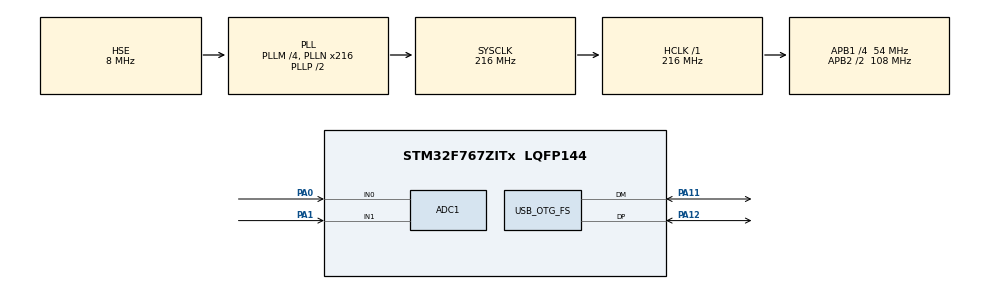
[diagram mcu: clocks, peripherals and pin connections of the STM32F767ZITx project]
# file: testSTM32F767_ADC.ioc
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ADC1.Channel-2\#ChannelRegularConversion=ADC_CHANNEL_1
ADC1.ClockPrescaler=ADC_CLOCK_SYNC_PCLK_DIV4
ADC1.ContinuousConvMode=ENABLE
ADC1.DMAContinuousRequests=ENABLE
ADC1.EOCSelection=ADC_EOC_SINGLE_CONV
ADC1.NbrOfConversion=2
ADC1.NbrOfConversionFlag=1
ADC1.Rank-2\#ChannelRegularConversion=2
ADC1.SamplingTime-0\#ChannelRegularConversion=ADC_SAMPLETIME_144CYCLES
ADC1.SamplingTime-2\#ChannelRegularConversion=ADC_SAMPLETIME_144CYCLES
ADC1.ScanConvMode=ADC_SCAN_ENABLE
ADC1.master=1
CORTEX_M7.ART_ACCLERATOR_ENABLE=1
CORTEX_M7.CPU_DCache=Enabled
CORTEX_M7.CPU_ICache=Enabled
CORTEX_M7.PREFETCH_ENABLE=1
Dma.ADC1.0.Direction=DMA_PERIPH_TO_MEMORY
Dma.ADC1.0.FIFOMode=DMA_FIFOMODE_DISABLE
Dma.ADC1.0.Instance=DMA2_Stream0
Dma.ADC1.0.MemDataAlignment=DMA_MDATAALIGN_HALFWORD
Dma.ADC1.0.MemInc=DMA_MINC_ENABLE
Dma.ADC1.0.Mode=DMA_CIRCULAR
Dma.ADC1.0.PeriphDataAlignment=DMA_PDATAALIGN_HALFWORD
Dma.ADC1.0.PeriphInc=DMA_PINC_DISABLE
Dma.ADC1.0.Priority=DMA_PRIORITY_MEDIUM
Dma.Request0=ADC1
Mcu.Family=STM32F7
Mcu.Name=STM32F767ZITx
Mcu.Package=LQFP144
NVIC.DMA2_Stream0_IRQn=true\:0\:0\:false\:false\:true\:false\:true
NVIC.OTG_FS_IRQn=true\:0\:0\:false\:false\:true\:false\:true
NVIC.PriorityGroup=NVIC_PRIORITYGROUP_4
NVIC.TIM2_IRQn=true\:0\:0\:false\:false\:true\:true\:true
PA0/WKUP.Signal=ADCx_IN0
PA1.Signal=ADCx_IN1
PA11.Mode=Device_Only
PA11.Signal=USB_OTG_FS_DM
PA12.Mode=Device_Only
PA12.Signal=USB_OTG_FS_DP
PH0/OSC_IN.Mode=HSE-External-Oscillator
PH0/OSC_IN.Signal=RCC_OSC_IN
PH1/OSC_OUT.Mode=HSE-External-Oscillator
PH1/OSC_OUT.Signal=RCC_OSC_OUT
ProjectManager.HeapSize=0x200
ProjectManager.StackSize=0x400
ProjectManager.TargetToolchain=SW4STM32
RCC.AHBFreq_Value=216000000
RCC.APB1CLKDivider=RCC_HCLK_DIV4
RCC.APB1Freq_Value=54000000
RCC.APB1TimFreq_Value=108000000
RCC.APB2CLKDivider=RCC_HCLK_DIV2
RCC.APB2Freq_Value=108000000
RCC.APB2TimFreq_Value=216000000
RCC.CortexFreq_Value=216000000
RCC.HCLKFreq_Value=216000000
RCC.HSE_VALUE=8000000
RCC.HSI_VALUE=16000000
RCC.LSE_VALUE=32768
RCC.PLLM=4
RCC.PLLN=216
RCC.PLLQ=9
RCC.SYSCLKFreq_VALUE=216000000
RCC.SYSCLKSource=RCC_SYSCLKSOURCE_PLLCLK
RCC.USBFreq_Value=48000000
RCC.VCOOutputFreq_Value=432000000
SH.ADCx_IN0.0=ADC1_IN0,IN0
SH.ADCx_IN1.0=ADC1_IN1,IN1
TIM2.Period=100
TIM2.Prescaler=5000
TIM2.TIM_MasterOutputTrigger=TIM_TRGO_UPDATE
USB_DEVICE.CLASS_NAME_FS=CDC
USB_DEVICE.VirtualMode-CDC_FS=Cdc
USB_DEVICE.VirtualModeFS=Cdc_FS
USB_OTG_FS.VirtualMode=Device_Only
VP_TIM2_VS_ClockSourceINT.Mode=Internal
VP_USB_DEVICE_VS_USB_DEVICE_CDC_FS.Mode=CDC_FS
board=custom

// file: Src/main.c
/* USER CODE BEGIN Header */
/**
  ******************************************************************************
  * @file           : main.c
  * @brief          : Main program body
  ******************************************************************************
  * @attention
  *
  * <h2><center>&copy; Copyright (c) 2020 STMicroelectronics.
  * All rights reserved.</center></h2>
  *
  * This software component is licensed by ST under BSD 3-Clause license,
  * the "License"; You may not use this file except in compliance with the
  * License. You may obtain a copy of the License at:
  *                        opensource.org/licenses/BSD-3-Clause
  *
  ******************************************************************************
  */
/* USER CODE END Header */

#include "main.h"
#include "usb_device.h"

ADC_HandleTypeDef hadc1;
DMA_HandleTypeDef hdma_adc1;

TIM_HandleTypeDef htim2;

void SystemClock_Config(void);
static void MX_GPIO_Init(void);
static void MX_DMA_Init(void);
static void MX_ADC1_Init(void);
static void MX_TIM2_Init(void);

/* USER CODE BEGIN 0 */
uint16_t adcdata[2]={0};

/* USER CODE END 0 */

int main(void)
{

  /* Enable I-Cache---------------------------------------------------------*/
  SCB_EnableICache();

  /* Enable D-Cache---------------------------------------------------------*/
  SCB_EnableDCache();

  /* MCU Configuration--------------------------------------------------------*/

  /* Reset of all peripherals, Initializes the Flash interface and the Systick. */
  HAL_Init();

  /* Configure the system clock */
  SystemClock_Config();

  /* Initialize all configured peripherals */
  MX_GPIO_Init();
  MX_DMA_Init();
  MX_ADC1_Init();
  MX_TIM2_Init();
  MX_USB_DEVICE_Init();
  /* USER CODE BEGIN 2 */

  HAL_ADC_Start_DMA(&hadc1, adcdata, sizeof(adcdata));
  uint8_t sendbuf[10]="Loop...";
  /* USER CODE END 2 */

  /* Infinite loop */
  while (1)
  {

    /* USER CODE BEGIN 3 */
	  HAL_Delay(10);
	  CDC_Transmit_FS(sendbuf, sizeof(sendbuf));
  }
  /* USER CODE END 3 */
}

void SystemClock_Config(void)
{
  RCC_OscInitTypeDef RCC_OscInitStruct = {0};
  RCC_ClkInitTypeDef RCC_ClkInitStruct = {0};
  RCC_PeriphCLKInitTypeDef PeriphClkInitStruct = {0};

  /** Configure the main internal regulator output voltage
  */
  __HAL_RCC_PWR_CLK_ENABLE();
  __HAL_PWR_VOLTAGESCALING_CONFIG(PWR_REGULATOR_VOLTAGE_SCALE1);
  /** Initializes the CPU, AHB and APB busses clocks
  */
  RCC_OscInitStruct.OscillatorType = RCC_OSCILLATORTYPE_HSE;
  RCC_OscInitStruct.HSEState = RCC_HSE_ON;
  RCC_OscInitStruct.PLL.PLLState = RCC_PLL_ON;
  RCC_OscInitStruct.PLL.PLLSource = RCC_PLLSOURCE_HSE;
  RCC_OscInitStruct.PLL.PLLM = 4;
  RCC_OscInitStruct.PLL.PLLN = 216;
  RCC_OscInitStruct.PLL.PLLP = RCC_PLLP_DIV2;
  RCC_OscInitStruct.PLL.PLLQ = 9;
  if (HAL_RCC_OscConfig(&RCC_OscInitStruct) != HAL_OK)
  {
    Error_Handler();
  }
  /** Activate the Over-Drive mode
  */
  if (HAL_PWREx_EnableOverDrive() != HAL_OK)
  {
    Error_Handler();
  }
  /** Initializes the CPU, AHB and APB busses clocks
  */
  RCC_ClkInitStruct.ClockType = RCC_CLOCKTYPE_HCLK|RCC_CLOCKTYPE_SYSCLK
                              |RCC_CLOCKTYPE_PCLK1|RCC_CLOCKTYPE_PCLK2;
  RCC_ClkInitStruct.SYSCLKSource = RCC_SYSCLKSOURCE_PLLCLK;
  RCC_ClkInitStruct.AHBCLKDivider = RCC_SYSCLK_DIV1;
  RCC_ClkInitStruct.APB1CLKDivider = RCC_HCLK_DIV4;
  RCC_ClkInitStruct.APB2CLKDivider = RCC_HCLK_DIV2;

  if (HAL_RCC_ClockConfig(&RCC_ClkInitStruct, FLASH_LATENCY_7) != HAL_OK)
  {
    Error_Handler();
  }
  PeriphClkInitStruct.PeriphClockSelection = RCC_PERIPHCLK_CLK48;
  PeriphClkInitStruct.Clk48ClockSelection = RCC_CLK48SOURCE_PLL;
  if (HAL_RCCEx_PeriphCLKConfig(&PeriphClkInitStruct) != HAL_OK)
  {
    Error_Handler();
  }
}

static void MX_ADC1_Init(void)
{

  ADC_ChannelConfTypeDef sConfig = {0};

  /** Configure the global features of the ADC (Clock, Resolution, Data Alignment and number of conversion)
  */
  hadc1.Instance = ADC1;
  hadc1.Init.ClockPrescaler = ADC_CLOCK_SYNC_PCLK_DIV4;
  hadc1.Init.Resolution = ADC_RESOLUTION_12B;
  hadc1.Init.ScanConvMode = ADC_SCAN_ENABLE;
  hadc1.Init.ContinuousConvMode = ENABLE;
  hadc1.Init.DiscontinuousConvMode = DISABLE;
  hadc1.Init.ExternalTrigConvEdge = ADC_EXTERNALTRIGCONVEDGE_NONE;
  hadc1.Init.ExternalTrigConv = ADC_SOFTWARE_START;
  hadc1.Init.DataAlign = ADC_DATAALIGN_RIGHT;
  hadc1.Init.NbrOfConversion = 2;
  hadc1.Init.DMAContinuousRequests = ENABLE;
  hadc1.Init.EOCSelection = ADC_EOC_SINGLE_CONV;
  if (HAL_ADC_Init(&hadc1) != HAL_OK)
  {
    Error_Handler();
  }
  /** Configure for the selected ADC regular channel its corresponding rank in the sequencer and its sample time.
  */
  sConfig.Channel = ADC_CHANNEL_1;
  sConfig.Rank = ADC_REGULAR_RANK_2;
  sConfig.SamplingTime = ADC_SAMPLETIME_144CYCLES;
  if (HAL_ADC_ConfigChannel(&hadc1, &sConfig) != HAL_OK)
  {
    Error_Handler();
  }
  /** Configure for the selected ADC regular channel its corresponding rank in the sequencer and its sample time.
  */
  sConfig.Channel = ADC_CHANNEL_0;
  sConfig.Rank = ADC_REGULAR_RANK_1;
  if (HAL_ADC_ConfigChannel(&hadc1, &sConfig) != HAL_OK)
  {
    Error_Handler();
  }

}

static void MX_TIM2_Init(void)
{

  TIM_ClockConfigTypeDef sClockSourceConfig = {0};
  TIM_MasterConfigTypeDef sMasterConfig = {0};

  htim2.Instance = TIM2;
  htim2.Init.Prescaler = 5000;
  htim2.Init.CounterMode = TIM_COUNTERMODE_UP;
  htim2.Init.Period = 100;
  htim2.Init.ClockDivision = TIM_CLOCKDIVISION_DIV1;
  htim2.Init.AutoReloadPreload = TIM_AUTORELOAD_PRELOAD_DISABLE;
  if (HAL_TIM_Base_Init(&htim2) != HAL_OK)
  {
    Error_Handler();
  }
  sClockSourceConfig.ClockSource = TIM_CLOCKSOURCE_INTERNAL;
  if (HAL_TIM_ConfigClockSource(&htim2, &sClockSourceConfig) != HAL_OK)
  {
    Error_Handler();
  }
  sMasterConfig.MasterOutputTrigger = TIM_TRGO_UPDATE;
  sMasterConfig.MasterSlaveMode = TIM_MASTERSLAVEMODE_DISABLE;
  if (HAL_TIMEx_MasterConfigSynchronization(&htim2, &sMasterConfig) != HAL_OK)
  {
    Error_Handler();
  }

}

static void MX_DMA_Init(void)
{

  /* DMA controller clock enable */
  __HAL_RCC_DMA2_CLK_ENABLE();

  /* DMA interrupt init */
  /* DMA2_Stream0_IRQn interrupt configuration */
  HAL_NVIC_SetPriority(DMA2_Stream0_IRQn, 0, 0);
  HAL_NVIC_EnableIRQ(DMA2_Stream0_IRQn);

}

static void MX_GPIO_Init(void)
{

  /* GPIO Ports Clock Enable */
  __HAL_RCC_GPIOH_CLK_ENABLE();
  __HAL_RCC_GPIOA_CLK_ENABLE();

}

void Error_Handler(void)
{
}

/************************ (C) COPYRIGHT STMicroelectronics *****END OF FILE****/
